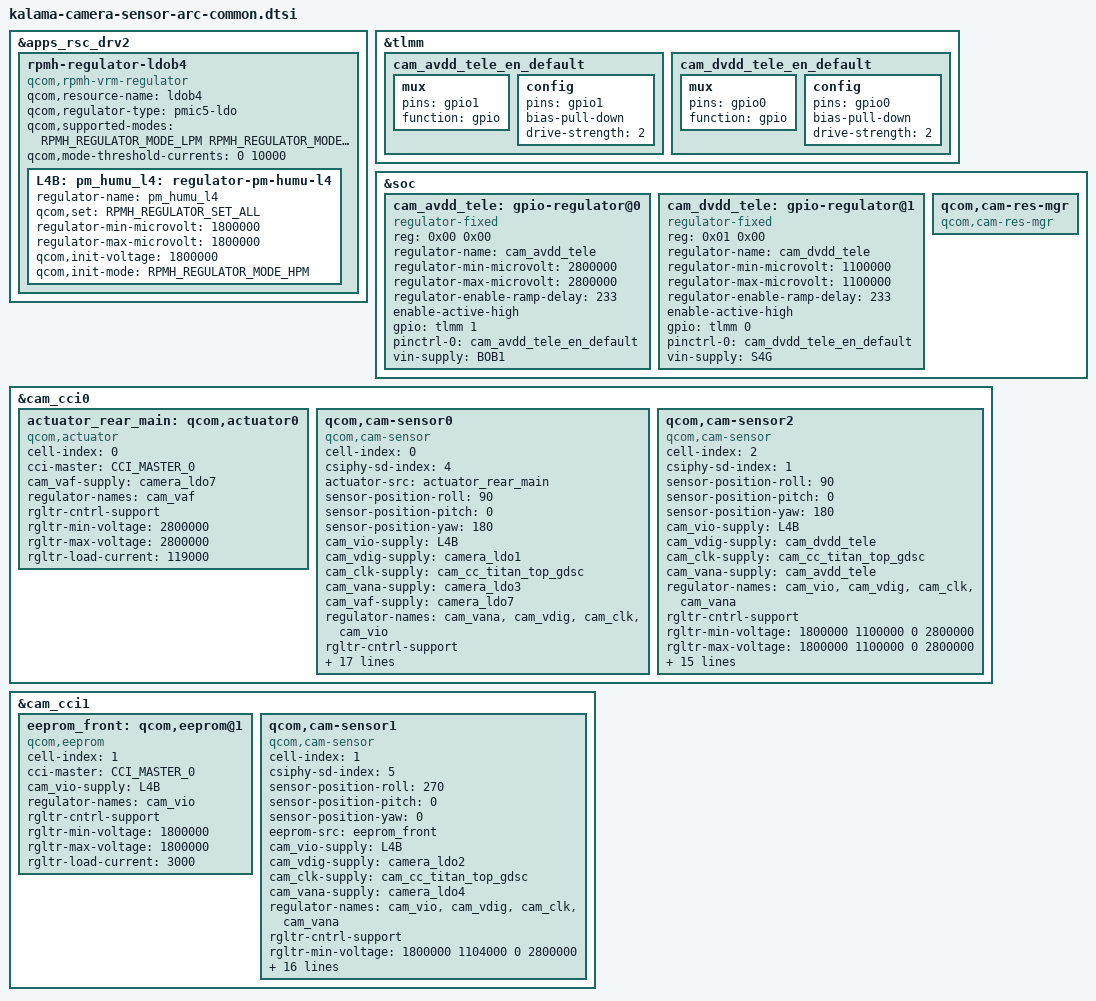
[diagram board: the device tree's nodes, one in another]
#include <dt-bindings/msm-camera.h>
#include <dt-bindings/regulator/qcom,rpmh-regulator-levels.h>

&apps_rsc_drv2 {
       rpmh-regulator-ldob4 {
               compatible = "qcom,rpmh-vrm-regulator";
               qcom,resource-name = "ldob4";
               qcom,regulator-type = "pmic5-ldo";
               qcom,supported-modes =
                       <RPMH_REGULATOR_MODE_LPM
                        RPMH_REGULATOR_MODE_HPM>;
               qcom,mode-threshold-currents = <0 10000>;

               L4B: pm_humu_l4: regulator-pm-humu-l4 {
                       regulator-name = "pm_humu_l4";
                       qcom,set = <RPMH_REGULATOR_SET_ALL>;
                       regulator-min-microvolt = <1800000>;
                       regulator-max-microvolt = <1800000>;
                       qcom,init-voltage = <1800000>;
                       qcom,init-mode = <RPMH_REGULATOR_MODE_HPM>;
               };
       };
};

&tlmm {
  /* tele s5kjn1 avdd*/
  cam_avdd_tele_en_default: cam_avdd_tele_en_default {
    mux {
      pins = "gpio1";
      function = "gpio";
    };

    config {
      pins = "gpio1";
      bias-pull-down; /* PULL DOWN */
      drive-strength = <2>; /* 2 MA */
    };
  };


  /* tele s5kjn1 dvdd*/
  cam_dvdd_tele_en_default: cam_dvdd_tele_en_default {
    mux {
      pins = "gpio0";
      function = "gpio";
    };

    config {
      pins = "gpio0";
      bias-pull-down; /* PULL DOWN */
      drive-strength = <2>; /* 2 MA */
    };
  };
};

&soc {
  /* tele s5kjn1 avdd*/
  cam_avdd_tele: gpio-regulator@0 {
    compatible = "regulator-fixed";
    reg = <0x00 0x00>;
    regulator-name = "cam_avdd_tele";
    regulator-min-microvolt = <2800000>;
    regulator-max-microvolt = <2800000>;
    regulator-enable-ramp-delay = <233>;
    enable-active-high;
    gpio = <&tlmm 1 0>;
    pinctrl-names = "default";
    pinctrl-0 = <&cam_avdd_tele_en_default>;
    vin-supply = <&BOB1>;
  };

  /* tele s5kjn1 dvdd*/
  cam_dvdd_tele: gpio-regulator@1 {
    compatible = "regulator-fixed";
    reg = <0x01 0x00>;
    regulator-name = "cam_dvdd_tele";
    regulator-min-microvolt = <1100000>;
    regulator-max-microvolt = <1100000>;
    regulator-enable-ramp-delay = <233>;
    enable-active-high;
    gpio = <&tlmm 0 0>;
    pinctrl-names = "default";
    pinctrl-0 = <&cam_dvdd_tele_en_default>;
    vin-supply = <&S4G>;
  };

  qcom,cam-res-mgr {
    compatible = "qcom,cam-res-mgr";
    status = "ok";
  };
};

&cam_cci0 {

  actuator_rear_main: qcom,actuator0{
		cell-index = <0>;
		compatible = "qcom,actuator";
		cci-master = <CCI_MASTER_0>;
		cam_vaf-supply = <&camera_ldo7>;
		regulator-names = "cam_vaf";
		rgltr-cntrl-support;
		rgltr-min-voltage = <2800000>;
		rgltr-max-voltage = <2800000>;
		rgltr-load-current = <119000>;
		status = "ok";
  };

  /* main s5kgn8 sensor*/
  qcom,cam-sensor0 {
  	cell-index = <0>;
	compatible = "qcom,cam-sensor";
	csiphy-sd-index = <4>;
	actuator-src = <&actuator_rear_main>;
	sensor-position-roll = <90>;
	sensor-position-pitch = <0>;
	sensor-position-yaw = <180>;
	cam_vio-supply = <&L4B>;
	cam_vdig-supply = <&camera_ldo1>;
	cam_clk-supply = <&cam_cc_titan_top_gdsc>;
	cam_vana-supply = <&camera_ldo3>;
	cam_vaf-supply = <&camera_ldo7>;
	regulator-names = "cam_vana",
		"cam_vdig","cam_clk","cam_vio";
	rgltr-cntrl-support;
	rgltr-min-voltage = <2200000 1000000 0 1800000>;
	rgltr-max-voltage = <2200000 1000000 0 1800000>;
	rgltr-load-current = <101000 787000 0 1000>;
	gpio-no-mux = <0>;

	pinctrl-names = "cam_default", "cam_suspend";
	pinctrl-0 = <&cam_sensor_mclk1_active
		&cam_sensor_active_rst2>;
	pinctrl-1 = <&cam_sensor_mclk1_suspend
		&cam_sensor_suspend_rst2>;
	gpios = <&tlmm 101 0>,
		<&tlmm 117 0>;
	gpio-reset = <1>;
	gpio-req-tbl-num = <0 1>;
	gpio-req-tbl-flags = <1 0>;
	gpio-req-tbl-label = "CAMIF_MCLK1",
			"CAM_RESET1";
	cci-master = <CCI_MASTER_0>;
	clocks = <&camcc CAM_CC_MCLK1_CLK>;
	clock-names = "cam_clk";
	clock-cntl-level = "nominal";
	clock-rates = <24000000>;
	status = "ok";
  };


  /* tele s5kjn1 sensor*/
  qcom,cam-sensor2 {
    cell-index = <2>;
    compatible = "qcom,cam-sensor";
    csiphy-sd-index = <1>;
    sensor-position-roll = <90>;
    sensor-position-pitch = <0>;
    sensor-position-yaw = <180>;

    cam_vio-supply = <&L4B>;
    cam_vdig-supply = <&cam_dvdd_tele>;
    cam_clk-supply = <&cam_cc_titan_top_gdsc>;
    cam_vana-supply = <&cam_avdd_tele>;
    regulator-names = "cam_vio", "cam_vdig", "cam_clk", "cam_vana";
    rgltr-cntrl-support;
    rgltr-min-voltage = <1800000 1100000 0 2800000>;
    rgltr-max-voltage = <1800000 1100000 0 2800000>;
    rgltr-load-current = <3500 125000 0 95000>;

    gpio-no-mux = <0>;
    pinctrl-names = "cam_default", "cam_suspend";
    pinctrl-0 = <&cam_sensor_mclk2_active &cam_sensor_active_rst2>;
    pinctrl-1 = <&cam_sensor_mclk2_suspend &cam_sensor_suspend_rst2>;
    gpios = <&tlmm 102 0>, <&tlmm 118 0>;
    gpio-reset = <1>;
    gpio-req-tbl-num = <0 1>;
    gpio-req-tbl-flags = <1 0>;
    gpio-req-tbl-label = "CAMIF_MCLK2", "CAM_RESET2";
    cci-master = <CCI_MASTER_1>;
    clocks = <&camcc CAM_CC_MCLK2_CLK>;
    clock-names = "cam_clk";
    clock-cntl-level = "nominal";
    clock-rates = <24000000>;
    status = "ok";
  };
};

&cam_cci1 {
	eeprom_front: qcom,eeprom@1 {
		cell-index = <1>;
		compatible = "qcom,eeprom";
		cci-master = <CCI_MASTER_0>;
		cam_vio-supply = <&L4B>;
		regulator-names = "cam_vio";
		rgltr-cntrl-support;
		rgltr-min-voltage = <1800000>;
		rgltr-max-voltage = <1800000>;
		rgltr-load-current = <3000>;
		status = "ok";
	};

	/* temp set ldo2 1.2V */
	qcom,cam-sensor1 {
		cell-index = <1>;
		compatible = "qcom,cam-sensor";
		csiphy-sd-index = <5>;
		sensor-position-roll = <270>;
		sensor-position-pitch = <0>;
		sensor-position-yaw = <0>;
		eeprom-src = <&eeprom_front>;
		cam_vio-supply = <&L4B>;
		cam_vdig-supply = <&camera_ldo2>;
		cam_clk-supply = <&cam_cc_titan_top_gdsc>;
		cam_vana-supply = <&camera_ldo4>;
		regulator-names = "cam_vio", "cam_vdig", "cam_clk",
			"cam_vana";
		rgltr-cntrl-support;
		rgltr-min-voltage = <1800000 1104000 0 2800000>;
		rgltr-max-voltage = <1800000 1104000 0 2800000>;
		rgltr-load-current = <10000 140400 0 52000>;
		gpio-no-mux = <0>;
		pinctrl-names = "cam_default", "cam_suspend";
		pinctrl-0 = <&cam_sensor_mclk4_active
				 &cam_sensor_active_rst4>;
		pinctrl-1 = <&cam_sensor_mclk4_suspend
				 &cam_sensor_suspend_rst4>;
		gpios = <&tlmm 104 0>,
			<&tlmm 120 0>;
		gpio-reset = <1>;
		gpio-req-tbl-num = <0 1>;
		gpio-req-tbl-flags = <1 0>;
		gpio-req-tbl-label = "CAMIF_MCLK4",
					"CAM_RESET4";
		cci-master = <CCI_MASTER_0>;
		clocks = <&camcc CAM_CC_MCLK4_CLK>;
		clock-names = "cam_clk";
		clock-cntl-level = "nominal";
		clock-rates = <24000000>;
		status = "ok";
	};
};
